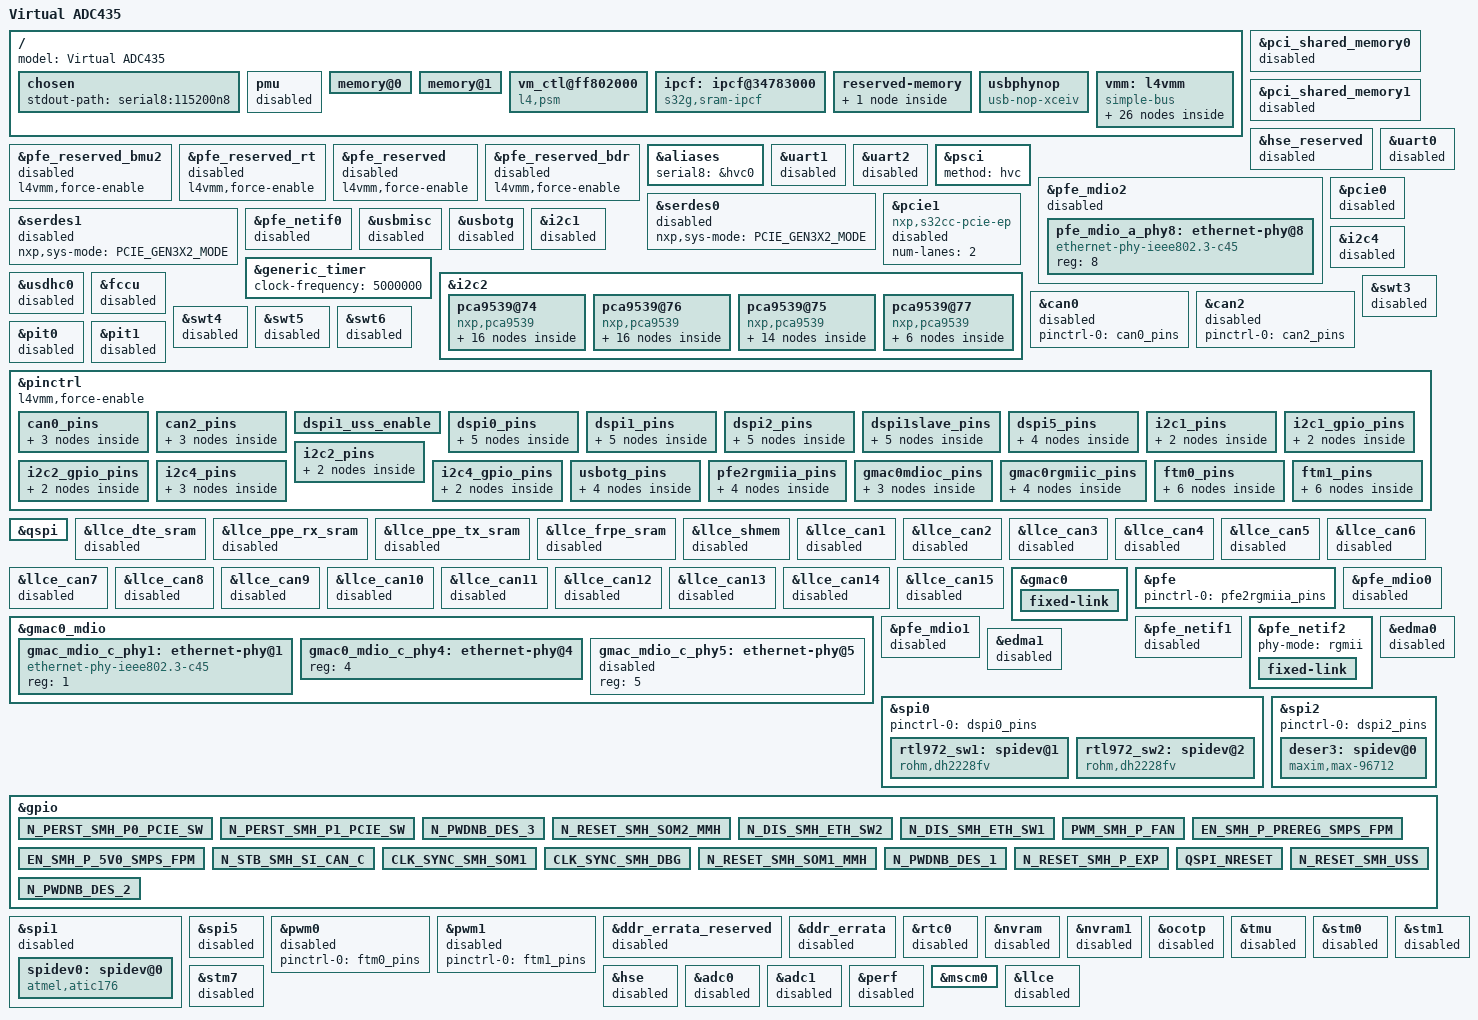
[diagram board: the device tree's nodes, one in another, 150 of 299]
// SPDX-License-Identifier: GPL-2.0-or-later
/*
 * Copyright 2023 Continental Automotive Technologies GmbH
 */

/dts-v1/;
#include <dt-bindings/gpio/gpio.h>
#include "s32g2.dtsi"
#include "micron-mt35xu01g-qspi-nor.dtsi"

/ {
	model = "Virtual ADC435";

	chosen {
		stdout-path = "serial8:115200n8";
	};

	pmu {
		status = "disabled";
	};

	memory@0 {
		device_type = "memory";
		reg = <0x00 0x00 0x00 0x80000000>;
		l4vmm,dscap = "ram";
	};

	memory@1 {
		device_type = "memory";
		reg = <0x00 0x00 0x00 0x80000000>;
		l4vmm,dscap = "ram2";
	};

	vm_ctl@ff802000 {
		compatible = "l4,psm";
		reg = <0x00 0xff802000 0x00 0x1000>;
		l4vmm,vbus-dev = "l4,psm";
	};

	ipcf: ipcf@34783000 {
			compatible = "s32g,sram-ipcf";
			reg = <0x00 0x34783000 0x00 0x3E800>;
			l4vmm,vbus-dev = "s32g,sram-ipcf";
	};


	reserved-memory {
		pfebufs@a0000000 {
			compatible = "shared-dma-pool";
			reg = <0x00 0xa0000000 0x00 0x3e0000>;
			no-map;
			l4vmm,force-enable;
		};
	};
		
	usbphynop: usbphynop {
		compatible = "usb-nop-xceiv";
		#phy-cells = <0>;
	};

	vmm: l4vmm {
		#address-cells = <1>;
		#size-cells = <1>;
		compatible = "simple-bus";
		ranges = <0x0 0x0 0xf1100000 0x40000>;

		virtio_rng@15000 {
			compatible = "virtio,mmio";
			reg = <0x20000 0x100 0 0>;
			interrupt-parent = <&gic>;
			interrupts = <GIC_SPI 122 IRQ_TYPE_LEVEL_HIGH>;
			l4vmm,vdev = "rng";
			l4vmm,virtiocap = "rng";
			status = "disabled";
			l4vmm,init-kaslr-seed;
		};

		hvc0: virtio_uart@20000 {
			compatible = "virtio,mmio";
			reg = <0x20000 0x100>;
			interrupt-parent = <&gic>;
			interrupts = <GIC_SPI 122 IRQ_TYPE_LEVEL_HIGH>;
			l4vmm,vdev = "console";
			status = "okay";
		};

		virtio_net@10000 {
			compatible = "virtio,mmio";
			reg = <0x10000 0x200>;
			interrupt-parent = <&gic>;
			interrupts = <GIC_SPI 123 IRQ_TYPE_LEVEL_HIGH>;
			l4vmm,vdev = "proxy";
			l4vmm,virtiocap = "net";
			status = "okay";
		};

		virtio_net@11000 {
			compatible = "virtio,mmio";
			reg = <0x11000 0x200>;
			interrupt-parent = <&gic>;
			interrupts = <GIC_SPI 125 IRQ_TYPE_LEVEL_HIGH>;
			l4vmm,vdev = "proxy";
			l4vmm,virtiocap = "net1";
			status = "disabled";
		};

		virtio_net@12000 {
			compatible = "virtio,mmio";
			reg = <0x12000 0x200>;
			interrupt-parent = <&gic>;
			interrupts = <GIC_SPI 126 IRQ_TYPE_LEVEL_HIGH>;
			l4vmm,vdev = "proxy";
			l4vmm,virtiocap = "net2";
			status = "disabled";
		};

		virtio_net@13000 {
			compatible = "virtio,mmio";
			reg = <0x13000 0x200>;
			interrupt-parent = <&gic>;
			interrupts = <GIC_SPI 127 IRQ_TYPE_LEVEL_HIGH>;
			l4vmm,vdev = "proxy";
			l4vmm,virtiocap = "net3";
			status = "disabled";
		};

		virtio_net@14000 {
			compatible = "virtio,mmio";
			reg = <0x14000 0x200>;
			interrupt-parent = <&gic>;
			interrupts = <GIC_SPI 128 IRQ_TYPE_LEVEL_HIGH>;
			l4vmm,vdev = "proxy";
			l4vmm,virtiocap = "net4";
			status = "disabled";
		};

		virtio_ser@21000 {
			compatible = "virtio,mmio";
			reg = <0x21000 0x200>;
			interrupt-parent = <&gic>;
			interrupts = <GIC_SPI 140 IRQ_TYPE_LEVEL_HIGH>;
			l4vmm,vdev = "proxy";
			l4vmm,virtiocap = "filed1";
			status = "disabled";
		};

		virtio_ser@22000 {
			compatible = "virtio,mmio";
			reg = <0x22000 0x200>;
			interrupt-parent = <&gic>;
			interrupts = <GIC_SPI 141 IRQ_TYPE_LEVEL_HIGH>;
			l4vmm,vdev = "proxy";
			l4vmm,virtiocap = "filed2";
			status = "disabled";
		};

		virtio_ser@23000 {
			compatible = "virtio,mmio";
			reg = <0x23000 0x200>;
			interrupt-parent = <&gic>;
			interrupts = <GIC_SPI 142 IRQ_TYPE_LEVEL_HIGH>;
			l4vmm,vdev = "proxy";
			l4vmm,virtiocap = "ser2";
			status = "disabled";
		};

		virtio_ser@24000 {
			compatible = "virtio,mmio";
			reg = <0x24000 0x200>;
			interrupt-parent = <&gic>;
			interrupts = <GIC_SPI 143 IRQ_TYPE_LEVEL_HIGH>;
			l4vmm,vdev = "proxy";
			l4vmm,virtiocap = "ser3";
			status = "disabled";
		};

		virtio_ser@25000 {
			compatible = "virtio,mmio";
			reg = <0x25000 0x200>;
			interrupt-parent = <&gic>;
			interrupts = <GIC_SPI 144 IRQ_TYPE_LEVEL_HIGH>;
			l4vmm,vdev = "proxy";
			l4vmm,virtiocap = "ser4";
			status = "disabled";
		};

		virtio_block@2000 {
			compatible = "virtio,mmio";
			reg = <0x2000 0x1000>;
			interrupt-parent = <&gic>;
			interrupts = <GIC_SPI 122 IRQ_TYPE_LEVEL_HIGH>;
			l4vmm,vdev = "proxy";
			l4vmm,virtiocap = "disk1";
			status = "okay";
		};
		virtio_block@3000 {
			compatible = "virtio,mmio";
			reg = <0x3000 0x1000>;
			interrupt-parent = <0x01>;
			interrupts = <0x00 0x83 0x04>;
			l4vmm,vdev = "proxy";
			l4vmm,virtiocap = "disk2";
			status = "okay";
		};

		virtio_block@4000 {
			compatible = "virtio,mmio";
			reg = <0x4000 0x1000>;
			interrupts = <0x00 0x84 0x04>;
			interrupt-parent = <0x01>;
			l4vmm,vdev = "proxy";
			l4vmm,virtiocap = "disk3";
			status = "okay";
		};

		virtio_block@5000 {
			compatible = "virtio,mmio";
			reg = <0x5000 0x1000>;
			interrupts = <0x00 0x85 0x04>;
			interrupt-parent = <0x01>;
			l4vmm,vdev = "proxy";
			l4vmm,virtiocap = "disk4";
			status = "okay";
		};

		virtio_block@6000 {
			compatible = "virtio,mmio";
			reg = <0x6000 0x1000>;
			interrupts = <0x00 0x86 0x04>;
			interrupt-parent = <0x01>;
			l4vmm,vdev = "proxy";
			l4vmm,virtiocap = "disk5";
			status = "okay";
		};

		virtio_block@7000 {
			compatible = "virtio,mmio";
			reg = <0x7000 0x1000>;
			interrupts = <0x00 0x87 0x04>;
			interrupt-parent = <0x01>;
			l4vmm,vdev = "proxy";
			l4vmm,virtiocap = "disk6";
			status = "okay";
		};

		virtio_block@8000 {
			compatible = "virtio,mmio";
			reg = <0x8000 0x1000>;
			interrupts = <0x00 0x88 0x04>;
			interrupt-parent = <0x01>;
			l4vmm,vdev = "proxy";
			l4vmm,virtiocap = "disk7";
			status = "okay";
		};

		virtio_block@9000 {
			compatible = "virtio,mmio";
			reg = <0x9000 0x1000>;
			interrupts = <0x00 0x89 0x04>;
			interrupt-parent = <0x01>;
			l4vmm,vdev = "proxy";
			l4vmm,virtiocap = "disk8";
			status = "okay";
		};

		virtio_block@a000 {
			compatible = "virtio,mmio";
			reg = <0xa000 0x1000>;
			interrupts = <0x00 0x8a 0x04>;
			interrupt-parent = <0x01>;
			l4vmm,vdev = "proxy";
			l4vmm,virtiocap = "disk9";
			status = "okay";
		};

		virtio_block@b000 {
			compatible = "virtio,mmio";
			reg = <0xb000 0x1000>;
			interrupts = <0x00 0x8b 0x04>;
			interrupt-parent = <0x01>;
			l4vmm,vdev = "proxy";
			l4vmm,virtiocap = "disk10";
			status = "okay";
		};

		virtio_block@c000 {
			compatible = "virtio,mmio";
			reg = <0xc000 0x1000>;
			interrupts = <0x00 0x8c 0x04>;
			interrupt-parent = <0x01>;
			l4vmm,vdev = "proxy";
			l4vmm,virtiocap = "disk11";
			status = "okay";
		};

		virtio_block@d000 {
			compatible = "virtio,mmio";
			reg = <0xd000 0x1000>;
			interrupts = <0x00 0x8d 0x04>;
			interrupt-parent = <0x01>;
			l4vmm,vdev = "proxy";
			l4vmm,virtiocap = "disk12";
			status = "okay";
		};

		virtio_block@e000 {
			compatible = "virtio,mmio";
			reg = <0xe000 0x1000>;
			interrupts = <0x00 0x8e 0x04>;
			interrupt-parent = <0x01>;
			l4vmm,vdev = "proxy";
			l4vmm,virtiocap = "disk13";
			status = "okay";
		};

		virtio_block@f000 {
			compatible = "virtio,mmio";
			reg = <0xf000 0x1000>;
			interrupts = <0x00 0x8f 0x04>;
			interrupt-parent = <0x01>;
			l4vmm,vdev = "proxy";
			l4vmm,virtiocap = "disk14";
			status = "okay";
		};
	};
};

&pci_shared_memory0 {
	device_type = "memory";
	status = "disabled";
};

&pci_shared_memory1 {
	device_type = "memory";
	status = "disabled";
};

&hse_reserved {
	device_type = "memory";
	status = "disabled";
};

&pfe_reserved_bmu2 {
	status = "enabled";
	l4vmm,force-enable;
};

&pfe_reserved_rt{
	status = "enabled";
	l4vmm,force-enable;
};

&pfe_reserved {
	status = "enabled";
	l4vmm,force-enable;
};

&pfe_reserved_bdr{
	status = "enabled";
	l4vmm,force-enable;
};

&aliases {
	serial8= &hvc0;
};

&uart0 {
	status = "disabled";
};

&uart1 {
	status = "disabled";
};

&uart2 {
	status = "disabled";
};

&psci {
	method = "hvc";
};

&pfe_mdio2 {
	/* AQR113 on S32G-PROCEVB3-S */
	pfe_mdio_a_phy8: ethernet-phy@8 {
		compatible = "ethernet-phy-ieee802.3-c45";
		reg = <8>;
	};
};

&serdes0 {
	nxp,sys-mode = <PCIE_GEN3X2_MODE>;
	status = "disabled";
};

&serdes1 {
	nxp,sys-mode = <PCIE_GEN3X2_MODE>;
	status = "disabled";
};

&pcie0 {
	status = "disabled";
};

&pcie1 {
	compatible = "nxp,s32cc-pcie-ep";
	num-lanes = <2>;
	status = "disabled";
};

&pfe_netif0 {
	phy-mode = "sgmii";
	phy-handle = <&pfe_mdio_a_phy8>;
	status = "disabled";
};

&usbmisc {
	status = "disabled";
};

&usbotg {
	pinctrl-names = "default";
	pinctrl-0 = <&usbotg_pins>;
	fsl,usbphy = <&usbphynop>;
	status = "disabled";
};

&generic_timer {
	clock-frequency = <5000000>;
};

&i2c1 {
	pinctrl-names = "default", "gpio";
	pinctrl-0 = <&i2c1_pins>;
	pinctrl-1 = <&i2c1_gpio_pins>;
	scl-gpios = <&gpio 163 (GPIO_ACTIVE_HIGH | GPIO_OPEN_DRAIN)>;
	sda-gpios = <&gpio 165 (GPIO_ACTIVE_HIGH | GPIO_OPEN_DRAIN)>;
	status = "disabled";
};

&i2c2 {
	pinctrl-names = "default", "gpio";
	pinctrl-0 = <&i2c2_pins>;
	pinctrl-1 = <&i2c2_gpio_pins>;
	scl-gpios = <&gpio 21 (GPIO_ACTIVE_HIGH | GPIO_OPEN_DRAIN)>;
	sda-gpios = <&gpio 22 (GPIO_ACTIVE_HIGH | GPIO_OPEN_DRAIN)>;
	status = "okay";
	/* GPIO expanders */
	pca9539@74 {
			compatible = "nxp,pca9539";
			reg = <0x74>;
			pinctrl-names = "default";
			gpio-controller;
			#gpio-cells = <0x02>;

			CAM1_EN {
				gpio-hog;
				gpios = <0 GPIO_ACTIVE_HIGH>;
			        output-low;
			        line-name = "CAM1_EN";
			};

			CAM2_EN {
				gpio-hog;
				gpios = <1 GPIO_ACTIVE_HIGH>;
			        output-low;
			        line-name = "CAM2_EN";
			};

			CAM3_EN {
				gpio-hog;
				gpios = <2 GPIO_ACTIVE_HIGH>;
				output-low;
			};

			CAM4_EN {
				gpio-hog;
				gpios = <3 GPIO_ACTIVE_HIGH>;
				output-low;
			};

			CAM5_EN {
				gpio-hog;
				gpios = <4 GPIO_ACTIVE_HIGH>;
				output-low;
			};

			CAM6_EN {
				gpio-hog;
				gpios = <5 GPIO_ACTIVE_HIGH>;
				output-low;
			};

			CAM7_EN {
				gpio-hog;
				gpios = <6 GPIO_ACTIVE_HIGH>;
				output-low;
			};

			CAM8_EN {
				gpio-hog;
				gpios = <7 GPIO_ACTIVE_HIGH>;
				output-low;
			};

			CAM9_EN {
				gpio-hog;
				gpios = <8 GPIO_ACTIVE_HIGH>;
				output-low;
			};

			CAM10_EN {
				gpio-hog;
				gpios = <9 GPIO_ACTIVE_HIGH>;
				output-low;
			};

			THER_EXP_HSSW {
				gpio-hog;
				gpios = <10 GPIO_ACTIVE_HIGH>;
				output-low;
			};

			I_SEH_EXP_HSSW {
				gpio-hog;
				gpios = <11 GPIO_ACTIVE_HIGH>;
				output-low;
			};

			I_SEL_EXP_HSSW {
				gpio-hog;
				gpios = <12 GPIO_ACTIVE_HIGH>;
				output-low;
			};

			DIAG_EN_EXP_HSSW1 {
				gpio-hog;
				gpios = <13 GPIO_ACTIVE_HIGH>;
				output-low;
			};

			DIAG_EN_EXP_HSSW2 {
				gpio-hog;
				gpios = <14 GPIO_ACTIVE_HIGH>;
				output-low;
			};

			DIAG_EN_EXP_HSSW3 {
				gpio-hog;
				gpios = <15 GPIO_ACTIVE_HIGH>;
				output-low;
			};
		};

		pca9539@76 {
			compatible = "nxp,pca9539";
			reg = <0x76>;
			gpio-controller;
			#gpio-cells = <0x02>;
			pinctrl-names = "default";

			EN_SMH_SI_3V3_SMPS_SYS {
				gpio-hog;
				gpios = <0 GPIO_ACTIVE_HIGH>;
				output-high;
				line-name = "EN_SMH_SI_3V3_SMPS_SYS";
			};

			EN_SMH_SI_1V8_SMPS_SYS {
				gpio-hog;
				gpios = <1 GPIO_ACTIVE_HIGH>;
				output-high;
			};

			EN_SMH_SI_1V2_SMPS_SYS {
				gpio-hog;
				gpios = <2 GPIO_ACTIVE_HIGH>;
				output-high;
			};

			EN_SMH_SI_1V1_SMPS_SYS {
				gpio-hog;
				gpios = <3 GPIO_ACTIVE_HIGH>;
				output-high;
			};

			EN_SMH_SI_0V9_SMPS_A_SYS {
				gpio-hog;
				gpios = <4 GPIO_ACTIVE_HIGH>;
				output-high;
			};

			EN_SMH_SI_0V9_SMPS_B_SYS {
				gpio-hog;
				gpios = <5 GPIO_ACTIVE_HIGH>;
				output-high;
			};

			EN_SMH_P_0V8_SMPS_AB {
				gpio-hog;
				gpios = <6 GPIO_ACTIVE_HIGH>;
				output-high;
			};

			EN_SMH_SI_CAN_FAS {
				gpio-hog;
				gpios = <7 GPIO_ACTIVE_HIGH>;
				output-high;
			};

			PG_3V3_SMPS_SYS_SMH_SI {
				gpio-hog;
				gpios = <8 GPIO_ACTIVE_HIGH>;
				input;
			};

			PG_1V8_SMPS_SYS_SMH_SI {
				gpio-hog;
				gpios = <9 GPIO_ACTIVE_HIGH>;
				input;
			};

			PG_1V2_SMPS_SYS_SMH_SI {
				gpio-hog;
				gpios = <10 GPIO_ACTIVE_HIGH>;
				input;
			};

			PG_1V1_SMPS_SYS_SMH_SI {
				gpio-hog;
				gpios = <11 GPIO_ACTIVE_HIGH>;
				input;
			};

			PG_0V9_SMPS_A_SYS_SMH_SI {
				gpio-hog;
				gpios = <12 GPIO_ACTIVE_HIGH>;
				input;
			};

			PG_0V9_SMPS_B_SYS_SMH_SI {
				gpio-hog;
				gpios = <13 GPIO_ACTIVE_HIGH>;
				input;
			};

			PG_0V8_SMPS_A_SMH_P {
				gpio-hog;
				gpios = <14 GPIO_ACTIVE_HIGH>;
				input;
			};

			PG_0V8_SMPS_B_SMH_P {
				gpio-hog;
				gpios = <15 GPIO_ACTIVE_HIGH>;
				input;
			};
		};

		pca9539@75 {
			compatible = "nxp,pca9539";
			reg = <0x75>;
			pinctrl-names = "default";
			gpio-controller;
			#gpio-cells = <0x02>;

			EN_SMH_P_PREREG_SMPS_IPM {
				gpio-hog;
				gpios = <0 GPIO_ACTIVE_HIGH>;
				output-high;
			};

			EN_SMH_P_5V0_SMPS_IPM {
				gpio-hog;
				gpios = <1 GPIO_ACTIVE_HIGH>;
				output-high;
			};

			EN_SMH_SI_CAN_C {
				gpio-hog;
				gpios = <2 GPIO_ACTIVE_HIGH>;
				output-high;
			};

			EN_SMH_P_PUMP_SMPS {
				gpio-hog;
				gpios = <3 GPIO_ACTIVE_HIGH>;
				output-high;
			};

			N_STB_SMH_SI_CAN_FAS {
				gpio-hog;
				gpios = <4 GPIO_ACTIVE_HIGH>;
				output-high;
			};

			N_RESET_SMH_P_CLK2 {
				gpio-hog;
				gpios = <5 GPIO_ACTIVE_HIGH>;
				output-high;
			};

			N_RESET_SMH_P_CLK1 {
				gpio-hog;
				gpios = <6 GPIO_ACTIVE_HIGH>;
				output-high;
			};

			N_RSTB_SMH_P_PCIE_SW {
				gpio-hog;
				gpios = <7 GPIO_ACTIVE_HIGH>;
				output-high;
			};

			PG_PREREG_SMPS_IPM_SMH_P {
				gpio-hog;
				gpios = <8 GPIO_ACTIVE_HIGH>;
				input;
			};

			PG_5V0_SMPS_IPM_SMH_P {
				gpio-hog;
				gpios = <9 GPIO_ACTIVE_HIGH>;
				input;
			};

			PG_PREREG_SMPS_FPM_SMH_P {
				gpio-hog;
				gpios = <10 GPIO_ACTIVE_HIGH>;
				input;
			};

			PG_5V0_SMPS_FPM_SMH_P {
				gpio-hog;
				gpios = <11 GPIO_ACTIVE_HIGH>;
				input;
			};

			PG_BUCK_BOOST {
				gpio-hog;
				gpios = <12 GPIO_ACTIVE_HIGH>;
				input;
			};

			PG_5V0_SMPS_SYS_SMH_SI {
				gpio-hog;
				gpios = <13 GPIO_ACTIVE_HIGH>;
				input;
			};
		};

		pca9539@77 {
			compatible = "nxp,pca9539";
			reg = <0x77>;
			pinctrl-names = "default";
			gpio-controller;
			#gpio-cells = <0x02>;

			ALERT_TEMP_1_SMH_P {
				gpio-hog;
				gpios = <0 GPIO_ACTIVE_HIGH>;
				input;
			};

			ALERT_TEMP_2_SMH_P {
				gpio-hog;
				gpios = <1 GPIO_ACTIVE_HIGH>;
				input;
			};

			ALERT_TEMP_3_SMH_P {
				gpio-hog;
				gpios = <2 GPIO_ACTIVE_HIGH>;
				input;
			};

			GPI2_SOM2_MMH_SMH {
				gpio-hog;
				gpios = <5 GPIO_ACTIVE_HIGH>;
				input;
		        };
		        N_RESET_SMH_P_ETH_SW1 {
				gpio-hog;
				gpios = <12 GPIO_ACTIVE_HIGH>;
				output-high;
		        };
		        N_RESET_SMH_P_ETH_SW2 {
				gpio-hog;
				gpios = <13 GPIO_ACTIVE_HIGH>;
				output-high;
			};
		};
};

&i2c4 {
	pinctrl-names = "default", "gpio";
	pinctrl-0 = <&i2c4_pins>;
	pinctrl-1 = <&i2c4_gpio_pins>;
	scl-gpios = <&gpio 34 (GPIO_ACTIVE_HIGH | GPIO_OPEN_DRAIN)>;
	sda-gpios = <&gpio 33 (GPIO_ACTIVE_HIGH | GPIO_OPEN_DRAIN)>;
	status = "disabled";
};

&usdhc0 {
	no-1-8-v;
	pinctrl-names = "default", "state_100mhz", "state_200mhz";
	pinctrl-0 = <&sd0_pins_default>;
	pinctrl-1 = <&sd0_pins_100mhz>;
	pinctrl-2 = <&sd0_pins_200mhz>;
	status = "disabled";
};

&can0 {
	pinctrl-names = "default";
	pinctrl-0 = <&can0_pins>;
	status = "disabled";
};

&can2 {
	pinctrl-names = "default";
	pinctrl-0 = <&can2_pins>;
	status = "disabled";
};

&fccu {
	status = "disabled";
};

&swt3 {
	status = "disabled";
};

&swt4 {
	status = "disabled";
};

&swt5 {
	status = "disabled";
};

&swt6 {
	status = "disabled";
};

&pit0 {
	status = "disabled";
};

&pit1 {
	status = "disabled";
};

&pinctrl {
	status = "okay";
	l4vmm,force-enable;
	can0_pins: can0_pins {
		can0_grp0 {
			pinmux = <S32CC_PINMUX(44, FUNC1)>; /*PC_12 -> TXD CANFD FAS*/
			output-enable;
			slew-rate = <S32CC_GPIO_3V3_SLEW_50MHZ>;
		};

		can0_grp1 {
			pinmux = <S32CC_PINMUX(43, FUNC0)>; /*PC_11 -> RXD CANFD FAS*/
			input-enable;
			slew-rate = <S32CC_GPIO_3V3_SLEW_50MHZ>;
		};

		can0_grp2 {
			pinmux = <S32CC_PINMUX(513, FUNC2)>; /*PC_11 -> RXD CANFD FAS*/
		};
	};

	can2_pins: can2_pins {
		can2_grp0 {
			pinmux = <S32CC_PINMUX(27, FUNC2)>; /* PB12*/
			output-enable;
			slew-rate = <S32CC_GPIO_3V3_SLEW_50MHZ>;
		};

		can2_grp1 {
			pinmux = <S32CC_PINMUX(28, FUNC0)>; /*PB11*/
			input-enable;
			slew-rate = <S32CC_GPIO_3V3_SLEW_50MHZ>;
		};

		can2_grp2 {
			pinmux = <S32CC_PINMUX(632, FUNC2)>;
		};
	};

	dspi1_uss_enable: dspi1_uss_enable {
		pinmux = <S32CC_PINMUX(98, FUNC0)>,/*PG02 -> N_RESET_USS*/
		         <S32CC_PINMUX(175, FUNC0)>; /*PK15 -> EN_USS*/
		output-enable;
		slew-rate = <S32CC_GPIO_3V3_SLEW_50MHZ>;
	};

	dspi0_pins: dspi0_pins {
		dspi0_grp0 {
			pinmux = <S32CC_PINMUX(25, FUNC5)>, /*PB_09 CS1 -> RTL9072 SW1*/
			         <S32CC_PINMUX(26, FUNC3)>; /*PB_10 CS2 -> RTL9072 SW2*/
			output-enable;
			slew-rate = <S32CC_GPIO_3V3_SLEW_50MHZ>;
			bias-pull-up;
		};

		dspi0_grp1 {
			pinmux = <S32CC_PINMUX(15, FUNC1)>; /*PA_15 -> MOSI*/
			output-enable;
			slew-rate = <S32CC_GPIO_3V3_SLEW_50MHZ>;
		};

		dspi0_grp2 {
			pinmux = <S32CC_PINMUX(13, FUNC1)>; /*PA_13 -> SCK*/
			output-enable;
			slew-rate = <S32CC_GPIO_3V3_SLEW_50MHZ>;
		};

		dspi0_grp3 {
			pinmux = <S32CC_PINMUX(14, FUNC0)>; /*PA_14 -> MISO*/
			input-enable;
			slew-rate = <S32CC_GPIO_3V3_SLEW_50MHZ>;
			bias-pull-up;
		};

		dspi0_grp4 {
			pinmux = <S32CC_PINMUX(982, FUNC2)>; /*PA_14 -> MISO*/
		};
	};

	dspi1_pins: dspi1_pins {
		dspi1_grp0 {
			pinmux = <S32CC_PINMUX(7, FUNC2)>;
			output-enable;
			slew-rate = <S32CC_GPIO_3V3_SLEW_50MHZ>;
			bias-pull-up;
		};

		dspi1_grp1 {
			pinmux = <S32CC_PINMUX(6, FUNC2)>;
			output-enable;
			slew-rate = <S32CC_GPIO_3V3_SLEW_50MHZ>;
		};

		dspi1_grp2 {
			pinmux = <S32CC_PINMUX(8, FUNC3)>;
			output-enable;
			slew-rate = <S32CC_GPIO_3V3_SLEW_50MHZ>;
		};

		dspi1_grp3 {
			pinmux = <S32CC_PINMUX(95, FUNC0)>;
			input-enable;
			slew-rate = <S32CC_GPIO_3V3_SLEW_50MHZ>;
			bias-pull-up;
		};

		dspi1_grp4 {
			pinmux = <S32CC_PINMUX(987, FUNC2)>;
		};
	};

	dspi2_pins: dspi2_pins {
		dspi2_grp0 {
			pinmux = <S32CC_PINMUX(155, FUNC2)>; /*PJ_11 -> CS*/
			output-enable;
			slew-rate = <S32CC_GPIO_3V3_SLEW_50MHZ>;
			bias-pull-up;
		};

		dspi2_grp1 {
			pinmux = <S32CC_PINMUX(157, FUNC2)>; /*PJ_13 -> MOSI*/
			output-enable;
			slew-rate = <S32CC_GPIO_3V3_SLEW_50MHZ>;
		};

		dspi2_grp2 {
			pinmux = <S32CC_PINMUX(153, FUNC2)>; /*PJ_09 -> SCK*/
			output-enable;
			slew-rate = <S32CC_GPIO_3V3_SLEW_50MHZ>;
		};

		dspi2_grp3 {
			pinmux = <S32CC_PINMUX(158, FUNC0)>; /*PJ_14 -> MISO*/
			input-enable;
			slew-rate = <S32CC_GPIO_3V3_SLEW_50MHZ>;
			bias-pull-up;
		};

		dspi2_grp4 {
			pinmux = <S32CC_PINMUX(992, FUNC3)>; /*PJ_14 -> MISO*/
		};
	};

	

	dspi1slave_pins: dspi1slave_pins {
		dspi1slave_grp0 {
			pinmux = <S32CC_PINMUX(6, FUNC2)>;
			output-enable;
			slew-rate = <S32CC_GPIO_3V3_SLEW_50MHZ>;
		};

		dspi1slave_grp1 {
			pinmux = <S32CC_PINMUX(7, FUNC2)>;
			input-enable;
			slew-rate = <S32CC_GPIO_3V3_SLEW_50MHZ>;
		};

		dspi1slave_grp2 {
			pinmux = <S32CC_PINMUX(985, FUNC2)>,
				 <S32CC_PINMUX(986, FUNC2)>,
				 <S32CC_PINMUX(987, FUNC2)>;
		};

		dspi1slave_grp3 {
			pinmux = <S32CC_PINMUX(8, FUNC3)>;
			input-enable;
			slew-rate = <S32CC_GPIO_3V3_SLEW_50MHZ>;
		};

		dspi1slave_grp4 {
			pinmux = <S32CC_PINMUX(95, FUNC0)>;
			input-enable;
			slew-rate = <S32CC_GPIO_3V3_SLEW_50MHZ>;
			bias-pull-up;
		};
	};

	dspi5_pins: dspi5_pins {
		dspi5_grp0 {
			pinmux = <S32CC_PINMUX(9, FUNC3)>,
				 <S32CC_PINMUX(11, FUNC3)>;
			output-enable;
			slew-rate = <S32CC_GPIO_3V3_SLEW_50MHZ>;
		};

		dspi5_grp1 {
			pinmux = <S32CC_PINMUX(10, FUNC0)>;
			input-enable;
			slew-rate = <S32CC_GPIO_3V3_SLEW_50MHZ>;
			bias-pull-up;
		};

		dspi5_grp2 {
			pinmux = <S32CC_PINMUX(1007, FUNC2)>;
		};

		dspi5_grp3 {
			pinmux = <S32CC_PINMUX(12, FUNC3)>;
			output-enable;
			slew-rate = <S32CC_GPIO_3V3_SLEW_50MHZ>;
			bias-pull-up;
		};
	};

	i2c1_pins: i2c1_pins {
		i2c1_grp0 {
			pinmux = <S32CC_PINMUX(163, FUNC3)>, /*PK_03 -> CLK*/
				 <S32CC_PINMUX(165, FUNC3)>; /*PK_05 -> SDA*/
			drive-open-drain;
			output-enable;
			input-enable;
			slew-rate = <S32CC_GPIO_3V3_SLEW_50MHZ>;
		};

		i2c1_grp1 {
			pinmux = <S32CC_PINMUX(717, FUNC5)>,
				 <S32CC_PINMUX(718, FUNC5)>;
		};

	};

	i2c1_gpio_pins: i2c1_gpio_pins {
		i2c1_gpio_grp0 {
			pinmux = <S32CC_PINMUX(163, FUNC0)>,
				 <S32CC_PINMUX(165, FUNC0)>;
			drive-open-drain;
			output-enable;
			slew-rate = <S32CC_GPIO_3V3_SLEW_50MHZ>;
		};

		i2c1_gpio_grp1 {
			pinmux = <S32CC_PINMUX(717, FUNC0)>,
				 <S32CC_PINMUX(718, FUNC0)>;
		};
	};

	i2c2_pins: i2c2_pins {
		i2c2_grp0 {
			pinmux = <S32CC_PINMUX(21, FUNC1)>, /*PB_05 -> SCL*/
				 <S32CC_PINMUX(22, FUNC1)>; /*PB_06 -> SDA*/
			drive-open-drain;
			output-enable;
			input-enable;
			slew-rate = <S32CC_GPIO_3V3_SLEW_50MHZ>;
		};

		i2c2_grp1 {
			pinmux = <S32CC_PINMUX(719, FUNC2)>,
				 <S32CC_PINMUX(720, FUNC2)>;
		};

	};

	i2c2_gpio_pins: i2c2_gpio_pins {
		i2c2_gpio_grp0 {
			pinmux = <S32CC_PINMUX(719, FUNC0)>,
				 <S32CC_PINMUX(720, FUNC0)>;
		};

		i2c2_gpio_grp1 {
			pinmux = <S32CC_PINMUX(21, FUNC0)>,
				 <S32CC_PINMUX(22, FUNC0)>;
			drive-open-drain;
			output-enable;
			slew-rate = <S32CC_GPIO_3V3_SLEW_50MHZ>;
		};

	};

	i2c4_pins: i2c4_pins {
		i2c4_grp0 {
			pinmux = <S32CC_PINMUX(33, FUNC1)>;
			drive-open-drain;
			output-enable;
			input-enable;
			slew-rate = <S32CC_GPIO_3V3_SLEW_50MHZ>;
		};

		i2c4_grp1 {
			pinmux = <S32CC_PINMUX(724, FUNC3)>,
				 <S32CC_PINMUX(723, FUNC3)>;
		};

		i2c4_grp2 {
			pinmux = <S32CC_PINMUX(34, FUNC2)>;
			drive-open-drain;
			output-enable;
			input-enable;
			slew-rate = <S32CC_GPIO_3V3_SLEW_50MHZ>;
		};
	};

	i2c4_gpio_pins: i2c4_gpio_pins {
		i2c4_gpio_grp0 {
			pinmux = <S32CC_PINMUX(33, FUNC0)>,
				 <S32CC_PINMUX(34, FUNC0)>;
			drive-open-drain;
			output-enable;
			slew-rate = <S32CC_GPIO_3V3_SLEW_50MHZ>;
		};

		i2c4_gpio_grp1 {
			pinmux = <S32CC_PINMUX(724, FUNC0)>,
				 <S32CC_PINMUX(723, FUNC0)>;
		};
	};

	usbotg_pins: usbotg_pins {
		usbotg_grp0 {
			pinmux = <S32CC_PINMUX(896, FUNC2)>,
				 <S32CC_PINMUX(897, FUNC2)>,
				 <S32CC_PINMUX(898, FUNC2)>,
				 <S32CC_PINMUX(899, FUNC2)>,
				 <S32CC_PINMUX(900, FUNC2)>,
				 <S32CC_PINMUX(901, FUNC2)>,
				 <S32CC_PINMUX(902, FUNC2)>,
				 <S32CC_PINMUX(903, FUNC2)>,
				 <S32CC_PINMUX(895, FUNC2)>,
				 <S32CC_PINMUX(904, FUNC2)>,
				 <S32CC_PINMUX(905, FUNC2)>;
		};

		usbotg_grp1 {
			pinmux = <S32CC_PINMUX(62, FUNC1)>,
				 <S32CC_PINMUX(63, FUNC1)>,
				 <S32CC_PINMUX(64, FUNC1)>,
				 <S32CC_PINMUX(65, FUNC1)>,
				 <S32CC_PINMUX(188, FUNC1)>,
				 <S32CC_PINMUX(189, FUNC1)>,
				 <S32CC_PINMUX(190, FUNC1)>,
				 <S32CC_PINMUX(112, FUNC1)>;
			output-enable;
			input-enable;
			slew-rate = <S32CC_GPIO_3V3_SLEW_50MHZ>;
		};

		usbotg_grp2 {
			pinmux = <S32CC_PINMUX(184, FUNC0)>,
				 <S32CC_PINMUX(185, FUNC0)>,
				 <S32CC_PINMUX(187, FUNC0)>;
			input-enable;
			slew-rate = <S32CC_GPIO_3V3_SLEW_50MHZ>;
		};

		usbotg_grp3 {
			pinmux = <S32CC_PINMUX(186, FUNC1)>;
			output-enable;
			slew-rate = <S32CC_GPIO_3V3_SLEW_50MHZ>;
		};
	};

	pfe2rgmiia_pins: pfe2rgmiia_pins {
		pfe2rgmiia_grp0 {
			pinmux = <S32CC_PINMUX(186, FUNC4)>, /*PL10 -> P9_TXD0*/
				 <S32CC_PINMUX(187, FUNC2)>, /*PL11 -> P9_TXD1*/
				 <S32CC_PINMUX(62, FUNC4)>, /*PD14 -> P9_TXD2*/
				 <S32CC_PINMUX(63, FUNC5)>, /*PD15 -> P9_TXD3*/
				 <S32CC_PINMUX(185, FUNC5)>; /*PL09 -> P9_TX_EN*/
			output-enable;
			slew-rate = <S32CC_GPIO_3V3_SLEW_50MHZ>;
		};

		pfe2rgmiia_grp1 {
			pinmux = <S32CC_PINMUX(188, FUNC0)>, /*PL12 -> P9_RXD0*/
				 <S32CC_PINMUX(189, FUNC0)>, /*PL13 -> P9_RXD1*/
				 <S32CC_PINMUX(190, FUNC0)>, /*PL14 -> P9_RXD2*/
				 <S32CC_PINMUX(112, FUNC0)>, /*PH00 -> P9_RXD3*/
				 <S32CC_PINMUX(64, FUNC0)>, /*PE00 -> P9_RX_CLK*/
				 <S32CC_PINMUX(65, FUNC0)>; /*PE01 -> P9_RX_DV*/
			input-enable;
			slew-rate = <S32CC_GPIO_3V3_SLEW_50MHZ>;
		};

		pfe2rgmiia_grp2 {
			pinmux = <S32CC_PINMUX(879, FUNC2)>,
				 <S32CC_PINMUX(885, FUNC2)>,
				 <S32CC_PINMUX(881, FUNC2)>,
				 <S32CC_PINMUX(882, FUNC2)>,
				 <S32CC_PINMUX(883, FUNC2)>,
				 <S32CC_PINMUX(884, FUNC2)>,
				 <S32CC_PINMUX(886, FUNC2)>;
		};

		pfe2rgmiia_grp3 {
			pinmux = <S32CC_PINMUX(184, FUNC5)>; /*PL08 -> P9_TX_CLK*/
			output-enable;
			slew-rate = <S32CC_GPIO_3V3_SLEW_50MHZ>;
			bias-pull-up;
		};
	};

	gmac0mdioc_pins: gmac0mdioc_pins {
		gmac0mdioc_grp0 {
			pinmux = <S32CC_PINMUX(60, FUNC1)>;
			output-enable;
			slew-rate = <S32CC_GPIO_3V3_SLEW_50MHZ>;
		};

		gmac0mdioc_grp1 {
			pinmux = <S32CC_PINMUX(61, FUNC1)>;
			output-enable;
			input-enable;
			slew-rate = <S32CC_GPIO_3V3_SLEW_50MHZ>;
		};

		gmac0mdioc_grp2 {
			pinmux = <S32CC_PINMUX(527, FUNC2)>;
		};
	};

	gmac0rgmiic_pins: gmac0rgmiic_pins {
		gmac0rgmiic_grp0 {
			pinmux = <S32CC_PINMUX(66, FUNC1)>;
			output-enable;
			slew-rate = <S32CC_GPIO_3V3_SLEW_50MHZ>;
			bias-pull-up;
		};

		gmac0rgmiic_grp1 {
			pinmux = <S32CC_PINMUX(538, FUNC2)>,
				 <S32CC_PINMUX(529, FUNC2)>,
				 <S32CC_PINMUX(530, FUNC2)>,
				 <S32CC_PINMUX(531, FUNC2)>,
				 <S32CC_PINMUX(532, FUNC2)>,
				 <S32CC_PINMUX(533, FUNC2)>,
				 <S32CC_PINMUX(534, FUNC2)>;
		};

		gmac0rgmiic_grp2 {
			pinmux = <S32CC_PINMUX(67, FUNC1)>,
				 <S32CC_PINMUX(68, FUNC1)>,
				 <S32CC_PINMUX(69, FUNC1)>,
				 <S32CC_PINMUX(70, FUNC1)>,
				 <S32CC_PINMUX(71, FUNC1)>;
			output-enable;
			slew-rate = <S32CC_GPIO_3V3_SLEW_50MHZ>;
		};

		gmac0rgmiic_grp3 {
			pinmux = <S32CC_PINMUX(72, FUNC0)>,
				 <S32CC_PINMUX(73, FUNC0)>,
				 <S32CC_PINMUX(74, FUNC0)>,
				 <S32CC_PINMUX(75, FUNC0)>,
				 <S32CC_PINMUX(76, FUNC0)>,
				 <S32CC_PINMUX(77, FUNC0)>;
			input-enable;
			slew-rate = <S32CC_GPIO_3V3_SLEW_50MHZ>;
		};
	};


	ftm0_pins: ftm0_pins {
		ftm0_grp0 {
			pinmux = <S32CC_PINMUX(657, FUNC2)>;
		};

		ftm0_grp1 {
			pinmux = <S32CC_PINMUX(18, FUNC2)>,
				 <S32CC_PINMUX(180, FUNC2)>;
			output-enable;
			input-enable;
			slew-rate = <S32CC_GPIO_3V3_SLEW_50MHZ>;
		};

		ftm0_grp2 {
			pinmux = <S32CC_PINMUX(177, FUNC3)>,
				 <S32CC_PINMUX(181, FUNC3)>;
			output-enable;
			input-enable;
			slew-rate = <S32CC_GPIO_3V3_SLEW_50MHZ>;
		};

		ftm0_grp3 {
			pinmux = <S32CC_PINMUX(656, FUNC4)>;
		};

		ftm0_grp4 {
			pinmux = <S32CC_PINMUX(658, FUNC5)>;
		};

		ftm0_grp5 {
			pinmux = <S32CC_PINMUX(659, FUNC6)>;
		};
	};

	ftm1_pins: ftm1_pins {
		ftm1_grp0 {
			pinmux = <S32CC_PINMUX(29, FUNC3)>;
			output-enable;
			input-enable;
			slew-rate = <S32CC_GPIO_3V3_SLEW_50MHZ>;
		};

		ftm1_grp1 {
			pinmux = <S32CC_PINMUX(667, FUNC4)>;
		};

		ftm1_grp2 {
			pinmux = <S32CC_PINMUX(668, FUNC3)>;
		};

		ftm1_grp3 {
			pinmux = <S32CC_PINMUX(31, FUNC4)>;
			output-enable;
			input-enable;
			slew-rate = <S32CC_GPIO_3V3_SLEW_50MHZ>;
		};

		ftm1_grp4 {
			pinmux = <S32CC_PINMUX(32, FUNC2)>;
			output-enable;
			input-enable;
			slew-rate = <S32CC_GPIO_3V3_SLEW_50MHZ>;
		};

		ftm1_grp5 {
			pinmux = <S32CC_PINMUX(669, FUNC2)>;
		};
	};
};

&qspi {
	status = "okay";
};

&llce_dte_sram {
	status = "disabled";
};

&llce_ppe_rx_sram {
	status = "disabled";
};

&llce_ppe_tx_sram {
	status = "disabled";
};

&llce_frpe_sram {
	status = "disabled";
};

&llce_shmem {
	status = "disabled";
};


&llce_can1 {
	status = "disabled";
};

&llce_can2 {
	status = "disabled";
};

&llce_can3 {
	status = "disabled";
};

&llce_can4 {
	status = "disabled";
};

&llce_can5 {
	status = "disabled";
};

&llce_can6 {
	status = "disabled";
};

&llce_can7 {
	status = "disabled";
};

&llce_can8 {
	status = "disabled";
};

&llce_can9 {
	status = "disabled";
};

&llce_can10 {
	status = "disabled";
};

&llce_can11 {
	status = "disabled";
};

&llce_can12 {
	status = "disabled";
};

&llce_can13 {
	status = "disabled";
};

&llce_can14 {
	/* LLCE CAN 14 uses the same transceiver as FLEXCAN2.
	 * By default, FLEXCAN2 is connected to the transceiver.
	 */
	status = "disabled";
};

&llce_can15 {
	/* LLCE CAN 15 uses the same transceiver as FLEXCAN3.
	 * By default, FLEXCAN3 is connected to the transceiver.
	 */
	status = "disabled";
};

&gmac0 {
	status = "okay";
	pinctrl-names = "default";
	pinctrl-0 = <&gmac0rgmiic_pins>, <&gmac0mdioc_pins>;
	phy-handle = <&gmac_mdio_c_phy1>;
	phy-mode = "rgmii-id";
	fixed-link {
	      speed = <1000>;
	      full-duplex;
	};

};


&gmac0_mdio {
	
	/* AQR107 on S32RGV-VNP-PLAT */
	gmac_mdio_c_phy1: ethernet-phy@1 {
		compatible = "ethernet-phy-ieee802.3-c45";
		reg = <1>;
	};
	/* KSZ9031RNX on S32G-PROCEVB-S/S32G-PROCEVB3-S */
	gmac0_mdio_c_phy4: ethernet-phy@4 {
		reg = <4>;
	};
	/* KSZ9031RNX on S32RGV-VNP-PLAT */
	gmac_mdio_c_phy5: ethernet-phy@5 {
		status = "disabled"; /* blocked by USB by default */
		reg = <5>;
	};
};
&pfe {
	status = "okay";
	pinctrl-names = "default";
	pinctrl-0 = <&pfe2rgmiia_pins>;
};

&pfe_mdio0 {
	/* used by USB ULPI */
	status = "disabled";
};

&pfe_mdio1 {
	/* unused */
	status = "disabled";
};

&pfe_mdio2 {
	/* unused */
	status = "disabled";
};

&pfe_netif1 {
	status = "disabled";
	/* phy-mode = "sgmii"; */
	/* phy-handle = <&gmac_mdio_c_phy1>; */
};

&pfe_netif2 {
	phy-mode = "rgmii";
	fixed-link {
		speed = <1000>;
		full-duplex;
	};
};

&edma0 {
	status = "disabled";
};

&edma1 {
	status = "disabled";
};


&spi0 {
	pinctrl-0 = <&dspi0_pins>;
	pinctrl-names = "default";
	#address-cells = <1>;
	#size-cells = <0>;
	status = "okay";

	rtl972_sw1: spidev@1 {
		compatible = "rohm,dh2228fv";
		spi-max-frequency = <4000000>;
		reg = <1>;
		fsl,spi-cs-sck-delay = <100>;
		fsl,spi-sck-cs-delay = <100>;
	};

	rtl972_sw2: spidev@2 {
		compatible = "rohm,dh2228fv";
		spi-max-frequency = <4000000>;
		reg = <2>;
		fsl,spi-cs-sck-delay = <100>;
		fsl,spi-sck-cs-delay = <100>;
	};
};

&spi2 {
	pinctrl-0 = <&dspi2_pins>;
	pinctrl-names = "default";
	#address-cells = <1>;
	#size-cells = <0>;
	status = "okay";

	deser3: spidev@0 {
		compatible = "maxim,max-96712";
		spi-max-frequency = <4000000>;
		reg = <0>;
		fsl,spi-cs-sck-delay = <100>;
		fsl,spi-sck-cs-delay = <100>;
	};
};

	/* misc_signals_bi: mis_signals_bi { */
	/* 	pinmux = <S32CC_PINMUX(120, FUNC0)>;/\*PH08 -> GPIO0_PCIE_SW*\/ */
	/* 	input-enable; */
	/* 	slew-rate = <S32CC_GPIO_3V3_SLEW_50MHZ>; */
	/* }; */
	
&gpio {
	N_PERST_SMH_P0_PCIE_SW {
		gpio-hog;
		gpios = <81 GPIO_ACTIVE_HIGH>;
		output-high;
		line-name = "N_PERST_SMH_P0_PCIE_SW";
	};

	N_PERST_SMH_P1_PCIE_SW {
		gpio-hog;
		gpios = <61 GPIO_ACTIVE_HIGH>;
		output-high;
		line-name = "N_PERST_SMH_P1_PCIE_SW";
	};
	
	N_PWDNB_DES_3 {
		gpio-hog;
		gpios = <83 GPIO_ACTIVE_HIGH>;
		output-high;
		line-name = "N_PWDNB_DES_3";
	};

	N_RESET_SMH_SOM2_MMH {
		gpio-hog;
		gpios = <121 GPIO_ACTIVE_HIGH>;
		output-high;
		line-name = "N_RESET_SMH_SOM2_MMH";
	};

	N_DIS_SMH_ETH_SW2 {
		gpio-hog;
		gpios = <159 GPIO_ACTIVE_HIGH>;
		output-high;
		line-name = "N_DIS_SMH_ETH_SW2";
	};

	N_DIS_SMH_ETH_SW1 {
		gpio-hog;
		gpios = <149 GPIO_ACTIVE_HIGH>;
		output-high;
		line-name = "N_DIS_SMH_ETH_SW1";
	};

	PWM_SMH_P_FAN {
		gpio-hog;
		gpios = <116 GPIO_ACTIVE_HIGH>;
		output-high;
		line-name = "PWM_SMH_P_FAN";
	};

	EN_SMH_P_PREREG_SMPS_FPM {
		gpio-hog;
		gpios = <122 GPIO_ACTIVE_HIGH>;
		output-high;
		line-name = "EN_SMH_P_PREREG_SMPS_FPM";
	};

	EN_SMH_P_5V0_SMPS_FPM {
		gpio-hog;
		gpios = <145 GPIO_ACTIVE_HIGH>;
		output-high;
		line-name = "EN_SMH_P_5V0_SMPS_FPM";
	};

	N_STB_SMH_SI_CAN_C {
		gpio-hog;
		gpios = <161 GPIO_ACTIVE_HIGH>;
		output-high;
		line-name = "N_STB_SMH_SI_CAN_C";
	};

	CLK_SYNC_SMH_SOM1 {
		gpio-hog;
		gpios = <11 GPIO_ACTIVE_HIGH>;
		output-high;
		line-name = "CLK_SYNC_SMH_SOM1";
	};

	CLK_SYNC_SMH_DBG {
		gpio-hog;
		gpios = <12 GPIO_ACTIVE_HIGH>;
		output-high;
		line-name = "CLK_SYNC_SMH_DBG";
	};

	N_RESET_SMH_SOM1_MMH {
		gpio-hog;
		gpios = <24 GPIO_ACTIVE_HIGH>;
		output-high;
		line-name = "N_RESET_SMH_SOM1_MMH";
	};

	N_PWDNB_DES_1 {
		gpio-hog;
		gpios = <57 GPIO_ACTIVE_HIGH>;
		output-high;
		line-name = "N_PWDNB_DES_1";
	};

	N_RESET_SMH_P_EXP {
		gpio-hog;
		gpios = <78 GPIO_ACTIVE_HIGH>;
		output-high;
		line-name = "N_RESET_SMH_P_EXP";
	};

	QSPI_NRESET {
		gpio-hog;
		gpios = <84 GPIO_ACTIVE_HIGH>;
		output-high;
		line-name = "QSPI_NRESET";
	};

	N_RESET_SMH_USS {
		gpio-hog;
		gpios = <98 GPIO_ACTIVE_HIGH>;
		output-high;
		line-name = "N_RESET_SMH_USS";
	};

	N_PWDNB_DES_2 {
		gpio-hog;
		gpios = <99 GPIO_ACTIVE_HIGH>;
		output-high;
		line-name = "N_PWDNB_DES_2";
	};
};

&spi1 {
	pinctrl-0 = <&dspi1_pins>, <&dspi1_uss_enable>;
	pinctrl-1 = <&dspi1slave_pins>;
	pinctrl-names = "default", "slave";
	#address-cells = <1>;
	#size-cells = <0>;
	status = "disabled";

	spidev0: spidev@0 {
		compatible = "atmel,atic176"; /* ??? there is no driver for it*/
		spi-max-frequency = <4000000>;
		reg = <0>;
		fsl,spi-cs-sck-delay = <100>;
		fsl,spi-sck-cs-delay = <100>;
	};
};

&spi5 {
	status = "disabled";
};

&pwm0 {
	pinctrl-names = "default";
	pinctrl-0 = <&ftm0_pins>;
	status = "disabled";
};

&pwm1 {
	pinctrl-names = "default";
	pinctrl-0 = <&ftm1_pins>;
	status = "disabled";
};

/* Thats dangerous, here we place the bootstrap image ...
we need to move it to another location
*/ 
&ddr_errata_reserved {
	device_type = "memory";
	status = "disabled";
};

&ddr_errata {
	status = "disabled";
};

&rtc0 {
	status = "disabled";
};

&nvram {
	status = "disabled";
};

&nvram1 {
	status = "disabled";
};

&ocotp {
	status = "disabled";
};

&tmu {
	status = "disabled";
};

&stm0 {
	status = "disabled";
};

&stm1 {
	status = "disabled";
};

&stm7 {
	status = "disabled";
};

&hse {
	status = "disabled";
};

&adc0 {
	status = "disabled";
};

&adc1 {
	status = "disabled";
};

&perf {
	status = "disabled";
};

&mscm0 {
	status = "okay";
};

&llce {
	status = "disabled";
};

